# APM32F446 register map
File version: 1.0
CPU: CM4 r0p1, little endian, MPU, FPU, 4 interrupt priority bits
Registers are 32-bit, read-write, reset 0x0 unless marked. A register's access mark holds for its fields unless they carry their own. Offsets are from the block's base; [hi:lo] are bit positions; {n}, {i} and the like mark numbered series; 'fields as' and 'values as' point back to an identical list.

## ADC0 — Analog-to-Digital Converter
Base 0x4003B000
Same registers: ADC1 0x40027000
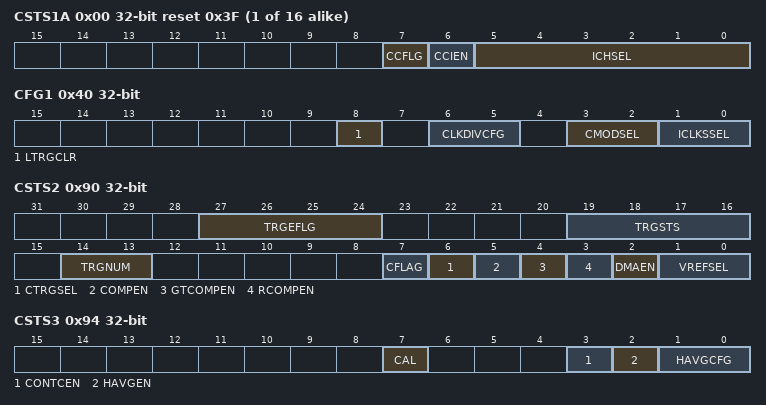
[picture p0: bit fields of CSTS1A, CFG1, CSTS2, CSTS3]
0x00 CSTS1{x} (x=A,B,C,D,E,F,G,H,I,J,K,L,M,N,O,P; step 0x4) reset 0x3F — Control and Status Register 1x
  [7] CCFLG ro — Input Clock Source Select
    0=Conversion is not completed; 1=Conversion is completed
  [6] CCIEN — Conversion Complete Interrupt Enable
    0=Conversion complete interrupt is disabled; 1=Conversion complete interrupt is enabled
  [5:0] ICHSEL — Input Channel Select
    {v}=Exernal channel {v} is selected as input (v=0..15); 21=Internal channel 0 is selected as input; 22=Internal channel 1 is selected as input; 23=Internal channel 2 is selected as input; 27=Band Gap; 28=Internal channel 3 is selected as input; 29=VREFSH is selected as input. Voltage reference selected is determined by CSTS2[REFSEL].; 30=VREFSL is selected as input. Voltage reference selected is determined by CSTS2[REFSEL].; {v}=Exernal channel {v-16} is selected as input (v=32..47); 63=Module is disabled
0x40 CFG1 — Configure Register 1
  [8] LTRGCLR wo — Latch Triggers Clear
  [6:5] CLKDIVCFG — Clock Divider Factor Configure
    0=The divide ratio is 1 and the clock rate is input clock; 1=The divide ratio is 2 and the clock rate is (input clock)/2; 2=The divide ratio is 4 and the clock rate is (input clock)/4; 3=The divide ratio is 8 and the clock rate is (input clock)/8
  [3:2] CMODSEL — Conversion Mode Select
    0=8-bit conversion; 1=12-bit conversion; 2=10-bit conversion
  [1:0] ICLKSSEL — Input Clock Source Select
    {v}=Alternate clock {v+1} (ADC_ALTCLK{v+1}) (v=0..3)
0x44 CFG2 reset 0xC — Configure Register 2
  [7:0] SMPTCFG — Sample Time Configure
0x48 DATA{x} (x=A,B,C,D,E,F,G,H,I,J,K,L,M,N,O,P; step 0x4) ro — Data Result Registers x
  [11:0] DATA — Conversion Data
{0x84+4i} COMPVAL{i} (i=1..2) — Compare Value Registers x
  [15:0] COMPVAL — Compare Value
0x90 CSTS2 — Status and Control Register 2
  [27:24] TRGEFLG ro — Trigger Error Occur Flag
    0=No error has occurred; 1=An error has occurred
  [19:16] TRGSTS ro — Trigger Status
    0=No trigger request has been latched; 1=A trigger request has been latched
  [14:13] TRGNUM ro — Trigger Number
  [7] CFLAG ro — Conversion Flag
    0=Conversion not in progress; 1=Conversion in progress
  [6] CTRGSEL — Software/Hardware Conversion Trigger Select
    0=Software trigger selected; 1=Hardware trigger selected
  [5] COMPEN — Compare Function Enable
    0=Compare function disabled; 1=Compare function enabled
  [4] GTCOMPEN — Greater Than Compare Function Enable
  [3] RCOMPEN — Range Compare Function Enable
  [2] DMAEN — DMA Mode Enable
    0=DMA is disabled; 1=DMA is enabled and will assert the ADC DMA request during an ADC conversion complete event , which is indicated when any CSTS1n[CCFLG] flag is asserted
  [1:0] VREFSEL — Voltage Reference Source Select
    0=Default voltage reference pin pair, that is, external pins VREFH and VREFL; 1=Alternate reference voltage, that is, VALTH. This voltage may be additional external pin or internal source depending on the MCU configuration. See the chip configuration information for details specific to this MCU.
0x94 CSTS3 — Status and Control Register 3
  [7] CAL — Calibration
  [3] CONTCEN — Continuous Conversion Mode Enable
    0=One conversion will be performed (or one set of conversions, if HAVGEN is set) after a conversion is initiated; 1=Continuous conversions will be performed (or continuous sets of conversions, if HAVGEN is set) after a conversion is initiated
  [2] HAVGEN — Hardware Average Function Enable
    0=Hardware average function disabled; 1=Hardware average function enabled
  [1:0] HAVGCFG — Hardware Averaged Samples Configure
    0=4 samples averaged; 1=8 samples averaged; 2=16 samples averaged; 3=32 samples averaged
0x98 BOEC reset 0x40 — Base Offset Error Correction Register
  [7:0] BOECVAL — Base Offset Error Correction Value
0x9C OEC — Offset Error Correction Register
  [15:0] OECVAL — Offset Error Correction Value
0xA0 UOEC — User defined Offset Error Correction Value Register
  [7:0] UOECVAL — User Defined Offset Error Correction Value
0xA4 XOEC reset 0x30 — X Offset Error Correction Register
  [5:0] XOECVAL — X Offset Error Correction Value
0xA8 YOEC reset 0x37 — Y Offset Error Correction Register
  [7:0] YOECVAL — Y Offset Error Correction Value
0xAC GEAF reset 0x2F0 — ADC Gain Error Adjustment Factor Register
  [10:0] GEAF — Gain Error Adjustment Factor
0xB0 UGEC reset 0x4 — User defined Gain Error Correction Register
  [9:0] UGECVAL — User defined Gain Error Correction Value
0xB4 GCALS reset 0x2E — General Calibration Register S
  [6:0] CALVAL — Calibration Value
0xB8 PSGCAL{x} (x=3,2,1,0; step 0x4) reset 0x180 — Plus-Side General Calibration Value Register x
  [9:0] CALVAL — Calibration Value
0xC8 PSGCALX — Plus-Side General Calibration Value Register X
  [6:0] CALVAL — Calibration Value
0xCC PSGCAL9 — Plus-Side General Calibration Value Register 9
  [6:0] CALVAL — CAL9
0xD0 GCALOS — General Calibration Offset Value Register S
  [3:0] COCVAL — Capacitor Offset Correction Value
0xD4 PSGCALOV{x} (x=3,2,1,0; step 0x4) — Plus-Side General Calibration Offset Value Register x
  [3:0] COCVAL — Capacitor Offset Correction Value
0xE4 PSGCALOV{x} (x=X,9; step 0x4) reset 0x440 — Plus-Side General Calibration Offset Value Register x
  [11:0] COCVAL — Capacitor Offset Correction Value
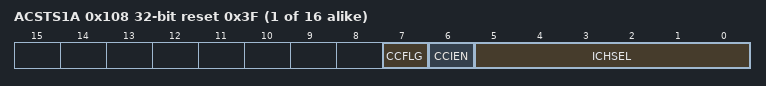
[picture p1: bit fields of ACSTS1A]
0x108 ACSTS1{x} (x=A,B,C,D,E,F,G,H,I,J,K,L,M,N,O,P; step 0x4) reset 0x3F — ADC Status and Control Register 1 (alias)
  [7] CCFLG ro — Input Clock Source Select
    0=Conversion is not completed; 1=Conversion is completed
  [6] CCIEN — Conversion Complete Interrupt Enable
    values as CSTS1{x}.CCIEN
  [5:0] ICHSEL — Input Channel Select
    0=Exernal intput channel 0 is selected; {v}=Exernal channel {v} is selected as input (v=1..15); 21=Internal channel 0 is selected as input; 22=Internal channel 1 is selected as input; 23=Internal channel 2 is selected as input; 27=Band Gap; 28=Internal channel 3 is selected as input; 29=VREFSH is selected as input. Voltage reference selected is determined by CSTS2[REFSEL].; 30=VREFSL is selected as input. Voltage reference selected is determined by CSTS2[REFSEL].; 31=Module is disabled; 32=Internal channel 16 is selected as input; {v}=Exernal channel {v-16} is selected as input (v=33..47); 0b11xxxx=Module is disabled
0x148 CSTS1{x} (x=Q,R,S,T,U,V,W,X; step 0x4) reset 0x3F — Control and Status Register 1x
  fields as ACSTS1{x}
0x188 ADATA{x} (x=A,B,C,D,E,F,G,H,I,J,K,L,M,N,O,P; step 0x4) ro — ADC Data Result Registers (alias)
  [11:0] DATA — Data result
0x1C8 DATA{x} (x=Q,R,S,T,U,V,W,X; step 0x4) ro — Data Result Registers x
  [11:0] DATA — Conversion Data
